# STM32H757_CM7 register map
File version: 1.3
CPU: CM7 r0p1, little endian, MPU, FPU, 4 interrupt priority bits
Registers are 32-bit, read-write, reset 0x0 unless marked. A register's access mark holds for its fields unless they carry their own. Offsets are from the block's base; [hi:lo] are bit positions; {n}, {i} and the like mark numbered series.

## ART — accelerator - control register (ART_CTR)
Base 0x40024400
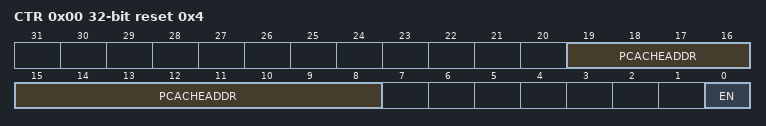
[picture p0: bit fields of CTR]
0x00 CTR reset 0x4 — control register
  [19:8] PCACHEADDR — Cacheable page index
  [0] EN — Cache enable

## Ethernet_MTL
Base 0x40028C00
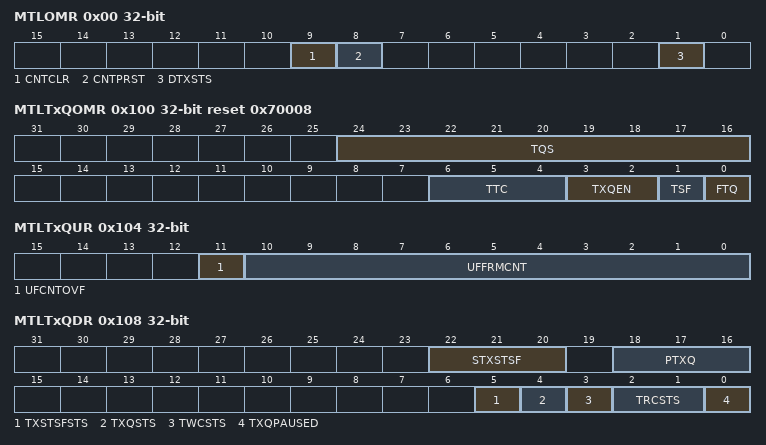
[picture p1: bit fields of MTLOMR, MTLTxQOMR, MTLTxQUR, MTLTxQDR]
0x00 MTLOMR access not given — Operating mode Register
  [9] CNTCLR — Counters Reset
  [8] CNTPRST — Counters Preset
  [1] DTXSTS — Drop Transmit Status
0x20 MTLISR access not given — Interrupt status Register
  [0] Q0IS — Queue interrupt status
0x100 MTLTxQOMR access not given reset 0x70008 — Tx queue operating mode Register
  [24:16] TQS — Transmit Queue Size
  [6:4] TTC — Transmit Threshold Control
  [3:2] TXQEN — Transmit Queue Enable
  [1] TSF — Transmit Store and Forward
  [0] FTQ — Flush Transmit Queue
0x104 MTLTxQUR access not given — Tx queue underflow register
  [11] UFCNTOVF — Overflow Bit for Underflow Packet Counter
  [10:0] UFFRMCNT — Underflow Packet Counter
0x108 MTLTxQDR access not given — Tx queue debug Register
  [22:20] STXSTSF — Number of Status Words in Tx Status FIFO of Queue
  [18:16] PTXQ — Number of Packets in the Transmit Queue
  [5] TXSTSFSTS — MTL Tx Status FIFO Full Status
  [4] TXQSTS — MTL Tx Queue Not Empty Status
  [3] TWCSTS — MTL Tx Queue Write Controller Status
  [2:1] TRCSTS — MTL Tx Queue Read Controller Status
  [0] TXQPAUSED — Transmit Queue in Pause
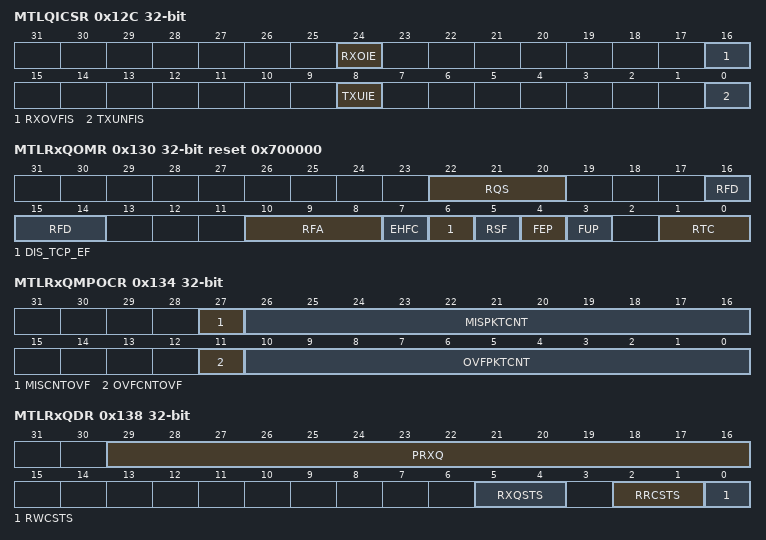
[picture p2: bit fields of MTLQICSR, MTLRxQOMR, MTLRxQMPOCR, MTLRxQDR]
0x12C MTLQICSR access not given — Queue interrupt control status Register
  [24] RXOIE — Receive Queue Overflow Interrupt Enable
  [16] RXOVFIS — Receive Queue Overflow Interrupt Status
  [8] TXUIE — Transmit Queue Underflow Interrupt Enable
  [0] TXUNFIS — Transmit Queue Underflow Interrupt Status
0x130 MTLRxQOMR access not given reset 0x700000 — Rx queue operating mode register
  [22:20] RQS — Receive Queue Size
  [16:14] RFD — Threshold for Deactivating Flow Control
  [10:8] RFA — Threshold for Activating Flow Control
  [7] EHFC — Enable Hardware Flow Control
  [6] DIS_TCP_EF — Disable Dropping of TCP
  [5] RSF — Receive Queue Store and Forward
  [4] FEP — Forward Error Packets
  [3] FUP — Forward Undersized Good Packets
  [1:0] RTC — Receive Queue Threshold Control
0x134 MTLRxQMPOCR access not given — Rx queue missed packet and overflow counter register
  [27] MISCNTOVF — Missed Packet Counter Overflow Bit
  [26:16] MISPKTCNT — Missed Packet Counter
  [11] OVFCNTOVF — Overflow Counter Overflow Bit
  [10:0] OVFPKTCNT — Overflow Packet Counter
0x138 MTLRxQDR access not given — Rx queue debug register
  [29:16] PRXQ — Number of Packets in Receive Queue
  [5:4] RXQSTS — MTL Rx Queue Fill-Level Status
  [2:1] RRCSTS — MTL Rx Queue Read Controller State
  [0] RWCSTS — MTL Rx Queue Write Controller Active Status

## RAMECC1 — RAM ECC monitoring
Base 0x52009000
Same registers: RAMECC2 0x48023000
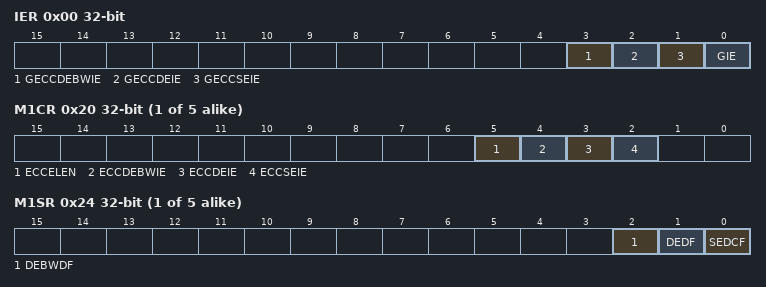
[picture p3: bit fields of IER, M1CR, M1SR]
0x00 IER — RAMECC interrupt enable register
  [3] GECCDEBWIE — Global ECC double error on byte write interrupt enable
  [2] GECCDEIE — Global ECC double error interrupt enable
  [1] GECCSEIE — Global ECC single error interrupt enable
  [0] GIE — Global interrupt enable
{0x0+0x20*i} M{i}CR (i=1..5) — RAMECC monitor {i} configuration register
  [5] ECCELEN — ECC error context latching enable
  [4] ECCDEBWIE — ECC double error on byte write interrupt enable
  [3] ECCDEIE — ECC double error interrupt enable
  [2] ECCSEIE — ECC single error interrupt enable
{0x4+0x20*i} M{i}SR (i=1..5) — RAMECC monitor {i} status register
  [2] DEBWDF — ECC double error on byte write flag
  [1] DEDF — ECC double error detected flag
  [0] SEDCF — ECC single error detected flag
{0x8+0x20*i} M{i}FAR (i=1..5) — RAMECC monitor {i} failing address register
  [31:0] FADD ro — ECC failing address
{0xC+0x20*i} M{i}FDRL (i=1..5) — RAMECC monitor {i} failing data low register
  [31:0] FDATAL ro — ECC failing data low
{0x10+0x20*i} M{i}FDRH (i=1..5) — RAMECC monitor {i} failing data high register
  [31:0] FDATAH ro — ECC failing data high
{0x14+0x20*i} M{i}FECR (i=1..5) — RAMECC monitor {i} failing error code register
  [31:0] FEC ro — ECC failing code

## RAMECC3 — RAM ECC monitoring
Base 0x58027000
Registers as RAMECC1, without M{n}CR (n=3..5), M{n}SR (n=3..5), M{n}FAR (n=3..5), M{n}FDRL (n=3..5), M{n}FDRH (n=3..5), M{n}FECR (n=3..5).
